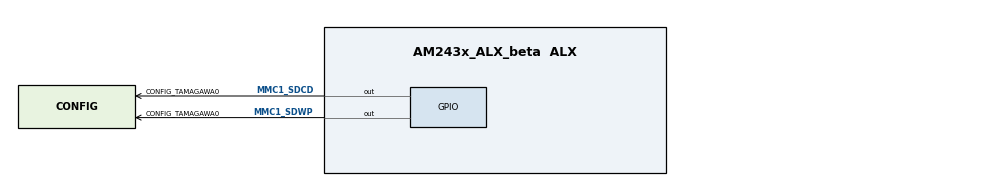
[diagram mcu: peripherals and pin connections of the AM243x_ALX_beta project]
/**
 * @cliArgs --device "AM243x_ALX_beta" --package "ALX" --part "ALX" --context "r5fss0-0" --product "MOTOR_CONTROL_SDK_AM243X@09.01.00"
 * @versions {"tool":"1.18.0+3266"}
 */

/**
 * Import the modules used in this configuration.
 */
const debug_log  = scripting.addModule("/kernel/dpl/debug_log");
const mpu_armv7  = scripting.addModule("/kernel/dpl/mpu_armv7", {}, false);
const mpu_armv71 = mpu_armv7.addInstance();
const mpu_armv72 = mpu_armv7.addInstance();
const mpu_armv73 = mpu_armv7.addInstance();
const mpu_armv74 = mpu_armv7.addInstance();
const mpu_armv75 = mpu_armv7.addInstance();
const tamagawa   = scripting.addModule("/position_sense/tamagawa", {}, false);
const tamagawa1  = tamagawa.addInstance();

/**
 * Write custom configuration values to the imported modules.
 */
debug_log.enableUartLog        = true;
debug_log.enableCssLog         = false;
debug_log.uartLog.$name        = "CONFIG_UART_CONSOLE";
debug_log.uartLog.UART.$assign = "USART0";

mpu_armv71.$name             = "CONFIG_MPU_REGION0";
mpu_armv71.size              = 31;
mpu_armv71.attributes        = "Device";
mpu_armv71.accessPermissions = "Supervisor RD+WR, User RD";
mpu_armv71.allowExecute      = false;

mpu_armv72.$name             = "CONFIG_MPU_REGION1";
mpu_armv72.size              = 15;
mpu_armv72.accessPermissions = "Supervisor RD+WR, User RD";

mpu_armv73.$name             = "CONFIG_MPU_REGION2";
mpu_armv73.baseAddr          = 0x41010000;
mpu_armv73.size              = 15;
mpu_armv73.accessPermissions = "Supervisor RD+WR, User RD";

mpu_armv74.$name             = "CONFIG_MPU_REGION3";
mpu_armv74.accessPermissions = "Supervisor RD+WR, User RD";
mpu_armv74.baseAddr          = 0x70000000;
mpu_armv74.size              = 21;

mpu_armv75.$name             = "CONFIG_MPU_REGION4";
mpu_armv75.baseAddr          = 0x60000000;
mpu_armv75.size              = 28;
mpu_armv75.accessPermissions = "Supervisor RD, User RD";

tamagawa1.$name                      = "CONFIG_TAMAGAWA0";
tamagawa1.Booster_Pack               = true;
tamagawa1.PRU_ICSSG0_PRU.$assign     = "PRU_ICSSG0_PRU1";
tamagawa1.PRU_ICSSG0_PRU.GPO5.$used  = false;
tamagawa1.PRU_ICSSG0_PRU.GPO4.$used  = false;
tamagawa1.PRU_ICSSG0_PRU.GPO3.$used  = false;
tamagawa1.PRU_ICSSG0_PRU.GPI14.$used = false;
tamagawa1.PRU_ICSSG0_PRU.GPO8.$used  = false;
tamagawa1.PRU_ICSSG0_PRU.GPO12.$used = false;
tamagawa1.PRU_ICSSG0_PRU.GPO6.$used  = false;
tamagawa1.PRU_ICSSG0_PRU.GPI11.$used = false;

tamagawa1.ENC1_EN.GPIO.$assign         = "GPIO1";
tamagawa1.ENC1_EN.$name                = "ENC1_EN";
tamagawa1.ENC1_EN.GPIO.gpioPin.pu_pd   = "pu";
tamagawa1.ENC1_EN.GPIO.gpioPin.rx      = false;
tamagawa1.ENC1_EN.GPIO.gpioPin.$assign = "MMC1_SDWP";

tamagawa1.ENC2_EN.$name                = "ENC2_EN";
tamagawa1.ENC2_EN.GPIO.gpioPin.pu_pd   = "pu";
tamagawa1.ENC2_EN.GPIO.gpioPin.rx      = false;
tamagawa1.ENC2_EN.GPIO.$assign         = "GPIO1";
tamagawa1.ENC2_EN.GPIO.gpioPin.$assign = "MMC1_SDCD";

const pruicss                            = scripting.addModule("/drivers/pruicss/pruicss", {}, false);
const pruicss1                           = pruicss.addInstance({}, false);
pruicss1.$name                           = "CONFIG_PRU_ICSS0";
tamagawa1.pru                            = pruicss1;
pruicss1.AdditionalICSSSettings[0].$name = "CONFIG_PRU_ICSS_IO0";
pruicss1.intcMapping.create(1);
pruicss1.intcMapping[0].$name            = "CONFIG_ICSS0_INTC_MAPPING0";
pruicss1.intcMapping[0].event            = "18";


/**
 * Pinmux solution for unlocked pins/peripherals. This ensures that minor changes to the automatic solver in a future
 * version of the tool will not impact the pinmux you originally saw.  These lines can be completely deleted in order to
 * re-solve from scratch.
 */
debug_log.uartLog.UART.RXD.$suggestSolution     = "ball.B10";
debug_log.uartLog.UART.TXD.$suggestSolution     = "ball.B11";
tamagawa1.PRU_ICSSG0_PRU.GPO2.$suggestSolution  = "ball.M2";
tamagawa1.PRU_ICSSG0_PRU.GPO1.$suggestSolution  = "ball.J2";
tamagawa1.PRU_ICSSG0_PRU.GPO0.$suggestSolution  = "ball.L5";
tamagawa1.PRU_ICSSG0_PRU.GPI13.$suggestSolution = "ball.T4";
